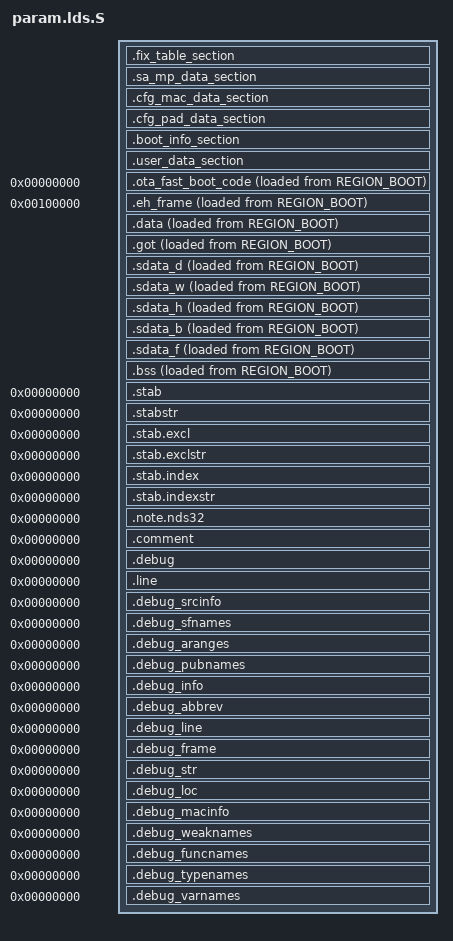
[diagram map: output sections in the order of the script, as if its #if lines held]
/* This file is generated by nds_ldsag (version (2015-08-19) ). */
#include <layout_flash_boot_ilm_dlm.lds.S>
#define M_FLASH_SECTOR_SIZE       (4096)
#define M_N10_LOOP          (0xD500)
ENTRY(g_sa_cfg)
EXTERN(g_wifi_cfg)
EXTERN(g_user_cfg)
SECTIONS
{
	_SDA_BASE_ = 0x00100000;
    __executable_start = 0x00000000;
    NDS_SAG_LMA_ROM = 0x30000000 ;
    FLASH_BEGIN = NDS_SAG_LMA_ROM;

    __xtal = XTAL;
    __sys_bus_speed = SYS_BUS_SPEED;
    __xip_bit = XIP_BIT;
    __setting_partition_main_size = SETTING_PARTITION_MAIN_SIZE;
    __setting_flash_total_size = SETTING_FLASH_TOTAL_SIZE;
    __setting_psram_heap_base = SETTING_PSRAM_HEAP_BASE;
    __setting_psram_heap_size = SETTING_PSRAM_HEAP_SIZE;
    __app_xip1                = ORIGIN(REGION_MAIN1);
    __app_xip2                = ORIGIN(REGION_MAIN2);

	. = ORIGIN(REGION_PARAM);
    .fix_table_section :
    {
         . = ALIGN(M_FLASH_SECTOR_SIZE);
         /* 0x4000 */
         __lds_ota_data_start = .;
         LONG(0xFFFFFFFF)
         KEEP(*(.ota_data))
         __lds_ota_data_end = .;
         . = ALIGN(M_FLASH_SECTOR_SIZE);
    }>REGION_PARAM

    .sa_mp_data_section :
    {
         . = ALIGN(M_FLASH_SECTOR_SIZE);
         /* 0x5000 */
         __lds_sa_mp_data_start = .;
         KEEP(*(.sa_mp_data))
         __lds_sa_mp_data_end = .;
         . = ALIGN(M_FLASH_SECTOR_SIZE);
    }>REGION_PARAM

    .cfg_mac_data_section :
    {
         . = ALIGN(M_FLASH_SECTOR_SIZE);
         /* 0x6000 */
         __lds_cfg_data_start = .;
         KEEP(*(.cfg_mac_data))
         __lds_cfg_data_end = .;
         . = ALIGN(M_FLASH_SECTOR_SIZE);
    }>REGION_PARAM

    .cfg_pad_data_section :
    {
        . = ALIGN(M_FLASH_SECTOR_SIZE);
         /* 0x7000 */
         __lds_pad_data_start = .;
         KEEP(*(.cfg_pad_data))
         __lds_pad_data_end = .;
         . = ALIGN(M_FLASH_SECTOR_SIZE);
    }>REGION_PARAM

    .boot_info_section :
    {
         . = ALIGN(M_FLASH_SECTOR_SIZE);
         /* 0x8000 */
         __lds_bootinfo_start = .;
         /* 0x8000 */
         BYTE(ROM_XTAL);
         BYTE(XIP_BIT);
         BYTE(SYS_BUS_SPEED);
#if defined(SETTING_ROM_BOOT) && (SETTING_ROM_BOOT==1)
         BYTE(0x6A);
#else
         BYTE(0x00);
#endif
         /* __lds_bootinfo_start + 0x04 */
         LONG(SETTING_OTA_METHOD)
         /* __lds_bootinfo_start + 0x08 */
         LONG(SETTING_UART_UPGRADE_EN)
         /* __lds_bootinfo_start + 0x0C */
         LONG(SETTING_ICACHE)
         /* __lds_bootinfo_start + 0x10 */
         LONG(SETTING_FLASH_TOTAL_SIZE)
         /* __lds_bootinfo_start + 0x14 */
         LONG(SETTING_PARTITION_USER_RAW_SIZE)
         /* __lds_bootinfo_start + 0x18 */
         LONG(SETTING_PARTITION_MAIN_SIZE)
         /* __lds_bootinfo_start + 0x1C */
         LONG(SETTING_UART_UPGRADE_BOOTLOADER)
         __lds_bootinfo_end = .;
         . = ALIGN(M_FLASH_SECTOR_SIZE);
    }>REGION_PARAM

    .user_data_section :
    {
        . = ALIGN(M_FLASH_SECTOR_SIZE);
         /* 0x9000 */
         __lds_user_data_start = .;
         KEEP(*(.user_data))
         __lds_user_data_end = .;
         . = ORIGIN(REGION_PARAM) + M_FLASH_SECTOR_SIZE  + M_FLASH_SECTOR_SIZE + M_FLASH_SECTOR_SIZE + M_FLASH_SECTOR_SIZE + M_FLASH_SECTOR_SIZE + SETTING_PARTITION_USER_RAW_SIZE - 2;
         SHORT(0x0);
         . = ALIGN(M_FLASH_SECTOR_SIZE);
    } > REGION_PARAM = 0
	
	. = 0x00000000;
	ILM_BEGIN = .;
	__ota_fast_boot_lmastart = LOADADDR(.ota_fast_boot_code);
	__ota_fast_boot_start = ADDR(.ota_fast_boot_code);
	.ota_fast_boot_code : 
	{
        *(.ota_fast_boot_code )
    } > REGION_TEXT_FAST AT>REGION_BOOT
	__ota_fast_boot_end = .;
	ILM_SIZE = . - ILM_BEGIN;
	. = 0x00100000;
    SDRAM_BEGIN = .;
	DLM_BEGIN = .;
    __data_lmastart =  LOADADDR (.eh_frame);
    __data_start = ADDR(.eh_frame);
    .eh_frame :
    {
        KEEP(*(.eh_frame ))
    } > REGION_DATA_FAST AT>REGION_BOOT
    .data :
    {
        *(.data .data.* .gnu.linkonce.d.* ) KEEP(*(.gnu.linkonce.d.*personality* )) SORT(CONSTRUCTORS) . = ALIGN(8);
    } > REGION_DATA_FAST AT>REGION_BOOT
    . = ALIGN(4);
    .got :
    {
        *(.got.plt ) *(.got )
    } > REGION_DATA_FAST AT>REGION_BOOT
    .sdata_d :
    {
        *(.sdata_d .sdata_d.* )
    } > REGION_DATA_FAST AT>REGION_BOOT
    .sdata_w :
    {
        *(.sdata_w .sdata_w.* )
    } > REGION_DATA_FAST AT>REGION_BOOT
    .sdata_h :
    {
        *(.sdata_h .sdata_h.* )
    } > REGION_DATA_FAST AT>REGION_BOOT
    .sdata_b :
    {
        *(.sdata_b .sdata_b.* )
    } > REGION_DATA_FAST AT>REGION_BOOT
    .sdata_f :
    {
        *(.sdata_f .sdata_f.* )
    } > REGION_DATA_FAST AT>REGION_BOOT
    . = ALIGN(4);
    _edata = .;
    PROVIDE (edata = .);
    __check_main_size = LOADADDR(.sdata_f) + SIZEOF(.sdata_f) - ORIGIN(REGION_BOOT);
    __bss_start = .;
    PROVIDE (__sbss_start = .);
    PROVIDE (___sbss_start = .);
    .bss  (NOLOAD) : ALIGN(4)
    {
        *(.tbss .tbss.* .gnu.linkonce.tb.* ) *(.tcommon )
        *(.sbss_f .sbss_f.* ) *(.scommon_f .scommon_f.* )
        *(.sbss_b .sbss_b.* ) *(.scommon_b .scommon_b.* ) . = ALIGN(2);
        *(.sbss_h .sbss_h.* ) *(.scommon_h .scommon_h.* ) . = ALIGN(4);
        *(.sbss_w .sbss_w.* ) *(.scommon_w .scommon_w.* ) *(.dynsbss ) *(.scommon ) . = ALIGN(8);
        *(.sbss_d .sbss_d.* ) *(.scommon_d .scommon_d.* )
        *(.dynbss ) *(.bss .bss.* .gnu.linkonce.b.* ) *(COMMON ) . = ALIGN(4);
    } > REGION_DATA_FAST AT>REGION_BOOT
    PROVIDE (__sbss_end = .);
    PROVIDE (___sbss_end = .);
    . = ALIGN(32);
    _end = .;
    PROVIDE (end = .);
    _show_dlm_end = .;
    PROVIDE (_show_dlm_end = .);

#ifndef MINIMAL_STACK_SIZE
#define MINIMAL_STACK_SIZE            (128)
#endif
    PROVIDE (_stack = ORIGIN(REGION_DATA_FAST)+LENGTH(REGION_DATA_FAST));
	__OS_Exception_Stack = _stack;
    __OS_Int_Stack = __OS_Exception_Stack - (MINIMAL_STACK_SIZE * 2);
    __fence__ = __OS_Int_Stack - (MINIMAL_STACK_SIZE * 6);
    dlm_remain = __fence__ - _end;
    SDRAM_SIZE = . - SDRAM_BEGIN;
    FLASH_SIZE = LOADADDR(.bss) - FLASH_BEGIN;

    .stab 0 :
    {
         *(.stab) 
    }
    .stabstr 0 :
    {
         *(.stabstr) 
    }
    .stab.excl 0 :
    {
         *(.stab.excl) 
    }
    .stab.exclstr 0 :
    {
         *(.stab.exclstr) 
    }
    .stab.index 0 :
    {
         *(.stab.index) 
    }
    .stab.indexstr 0 :
    {
         *(.stab.indexstr) 
    }
    .note.nds32 0 :
    {
         *(.note.nds32) *(.note.nds32.*) 
    }
    .comment 0 :
    {
         *(.comment) 
    }
    .debug 0 :
    {
         *(.debug) 
    }
    .line 0 :
    {
         *(.line) 
    }
    .debug_srcinfo 0 :
    {
         *(.debug_srcinfo) 
    }
    .debug_sfnames 0 :
    {
         *(.debug_sfnames) 
    }
    .debug_aranges 0 :
    {
         *(.debug_aranges) 
    }
    .debug_pubnames 0 :
    {
         *(.debug_pubnames) 
    }
    .debug_info 0 :
    {
         *(.debug_info .gnu.linkonce.wi.*) 
    }
    .debug_abbrev 0 :
    {
         *(.debug_abbrev) 
    }
    .debug_line 0 :
    {
         *(.debug_line) 
    }
    .debug_frame 0 :
    {
         *(.debug_frame) 
    }
    .debug_str 0 :
    {
         *(.debug_str) 
    }
    .debug_loc 0 :
    {
         *(.debug_loc) 
    }
    .debug_macinfo 0 :
    {
         *(.debug_macinfo) 
    }
    .debug_weaknames 0 :
    {
         *(.debug_weaknames) 
    }
    .debug_funcnames 0 :
    {
         *(.debug_funcnames) 
    }
    .debug_typenames 0 :
    {
         *(.debug_typenames) 
    }
    .debug_varnames 0 :
    {
         *(.debug_varnames) 
    }
}

#if (defined(ROM_MODE) && (ROM_MODE == 1))
#include "rom_symbol.sym"
#endif
